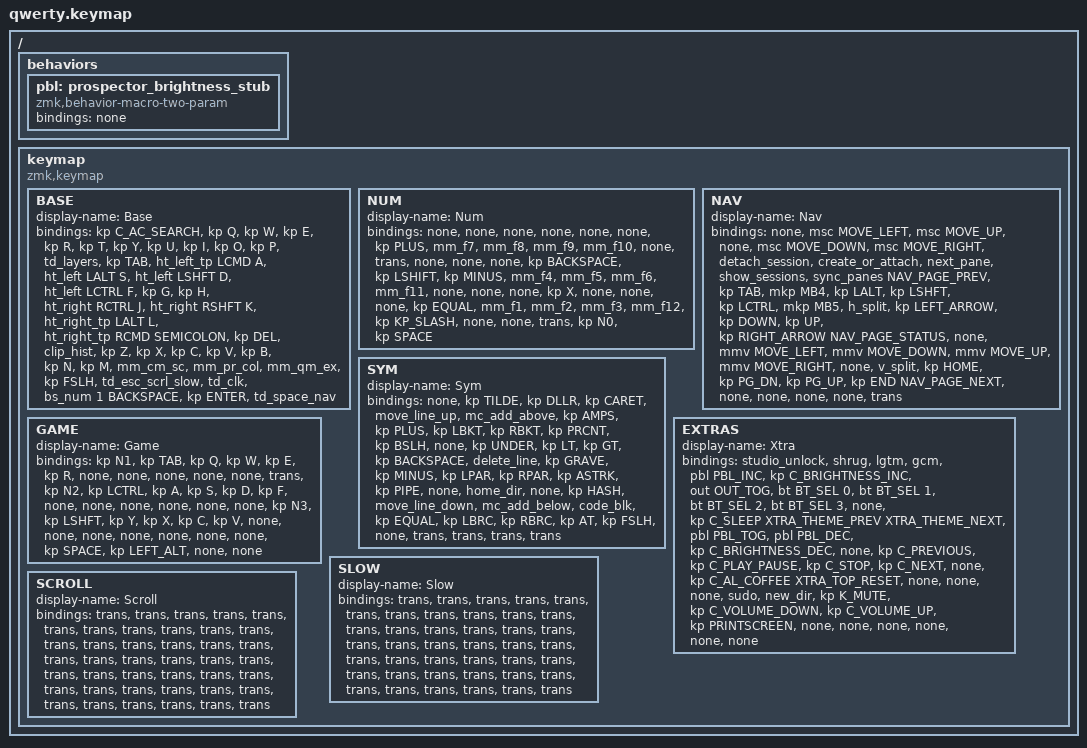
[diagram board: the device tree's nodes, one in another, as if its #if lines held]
/* upstream bindings and behaviors */
#include <behaviors.dtsi>
#include <dt-bindings/zmk/bt.h>
#include <dt-bindings/zmk/keys.h>
#include <dt-bindings/zmk/mouse.h>
#include <dt-bindings/zmk/outputs.h>
#include <behaviors/mouse_keys.dtsi>
#include <dt-bindings/zmk/ext_power.h>

/* The shield-specific overlay provides this before keymap preprocessing. */
#ifdef CHARYBDIS_PROSPECTOR_ADAPTER
#include <dt-bindings/prospector/display_page.h>
#include <dt-bindings/prospector/theme.h>
#define NAV_PAGE_PREV &pdp PDP_PREV
#define NAV_PAGE_STATUS &pdp PDP_STATUS
#define NAV_PAGE_NEXT &pdp PDP_NEXT
#define XTRA_THEME_PREV &pth PTH_PREV
#define XTRA_THEME_NEXT &pth PTH_NEXT
#define XTRA_TOP_RESET &ptr
#else
#define NAV_PAGE_PREV &none
#define NAV_PAGE_STATUS &none
#define NAV_PAGE_NEXT &none
#define XTRA_THEME_PREV &none
#define XTRA_THEME_NEXT &none
#define XTRA_TOP_RESET &none
#endif

/* local overlays */
#include "keymap_features/prospector_brightness.dtsi"
#include "keymap_features/macros.dtsi"
#include "keymap_features/behaviors.dtsi"
#include "keymap_features/combos.dtsi"

/ {
/* --- KEYMAP CONFIG --- */
// ╭──────┬──────┬──────┬──────┬──────┬──────╮  ╭──────┬──────┬──────┬──────┬──────┬──────╮
//    00     01     02     03    04      05        06     07     08     09     10     11
// ├──────┼──────┼──────┼──────┼──────┼──────┤  ├──────┼──────┼──────┼──────┼──────┼──────┤
//    12     13     14     15    16      17        18     19     20     21     22     23
// ├──────┼──────┼──────┼──────┼──────┼──────┤  ├──────┼──────┼──────┼──────┼──────┼──────┤
//    24     25     26     27    28      29        30     31     32     33     34     35
// ╰──────┴──────┴──────┼──────┼──────┼──────┤  ├──────┼──────┼──────┴──────┴──────┴──────╯
//                         36     37     38        39     40
//                      ╰──────┴──────┴──────╯  ╰──────┴──────╯
// #define BASE    0
// #define NUM     1
// #define NAV     2
// #define SYM     3
// #define GAME    4
// #define EXTRAS  5
// #define SLOW    6
// #define SCROLL  7

// This shared keymap builds for prospector and non-prospector firmwares. 
// This stubs the key bindings that are contained in the prospector module
// so non-prospector firmware can build.
#ifndef CONFIG_SHIELD_PROSPECTOR_ADAPTER
    behaviors {
        /omit-if-no-ref/ pbl: prospector_brightness_stub {
            compatible = "zmk,behavior-macro-two-param";
            #binding-cells = <2>;
            bindings = <&none>;
        };
    };
#endif

    keymap {
        compatible = "zmk,keymap";
        BASE {
            display-name = "Base";
            bindings = <
// ╭───────────────┬────────────────┬────────────────┬─────────────────┬─────────────────┬──────╮  ╭──────┬──────────────────┬──────────────────┬─────────────────┬─────────────────┬─────────────╮
    &kp C_AC_SEARCH  &kp Q            &kp W            &kp E             &kp R             &kp T    &kp Y   &kp U              &kp I              &kp O             &kp P           &td_layers
// ├───────────────┼────────────────┼────────────────┼─────────────────┼─────────────────┼──────┤  ├──────┼──────────────────┼──────────────────┼─────────────────┼─────────────────┼─────────────┤
    &kp TAB          &ht_left_tp LCMD A  &ht_left LALT S  &ht_left LSHFT D  &ht_left LCTRL F  &kp G    &kp H   &ht_right RCTRL J  &ht_right RSHFT K  &ht_right_tp LALT L  &ht_right_tp RCMD SEMICOLON   &kp DEL
// ├───────────────┼────────────────┼────────────────┼─────────────────┼─────────────────┼──────┤  ├──────┼──────────────────┼──────────────────┼─────────────────┼─────────────────┼─────────────┤
    &clip_hist       &kp Z            &kp X            &kp C             &kp V             &kp B    &kp N   &kp M              &mm_cm_sc          &mm_pr_col        &mm_qm_ex          &kp FSLH
// ╰───────────────┴────────────────┴────────────────┼─────────────────┼─────────────────┼──────┤  ├──────┼──────────────────┼──────────────────┴─────────────────┴─────────────────┴─────────────╯
                                                             &td_esc_scrl_slow   &td_clk  &bs_num 1 BACKSPACE   &kp ENTER  &td_space_nav
                                                         // ╰──────────────────┴─────────┴──────╯  ╰──────────┴──────────────╯
            >;
        };

        NUM {
            display-name = "Num";
            bindings = <
&none   &none  &none   &none  &none          &none            &kp PLUS     &mm_f7             &mm_f8             &mm_f9             &mm_f10            &none
&trans   &none  &none  &none  &kp BACKSPACE  &kp LSHIFT       &kp MINUS    &mm_f4             &mm_f5             &mm_f6             &mm_f11            &none
&none    &none  &kp X  &none  &none          &none            &kp EQUAL    &mm_f1             &mm_f2             &mm_f3             &mm_f12            &kp KP_SLASH
                       &none  &none          &trans           &kp N0     &kp SPACE
            >;
        };

        NAV {
            display-name = "Nav";
            bindings = <
&none    &msc MOVE_LEFT  &msc MOVE_UP    &none        &msc MOVE_DOWN  &msc MOVE_RIGHT     &detach_session  &create_or_attach  &next_pane   &show_sessions  &sync_panes       NAV_PAGE_PREV
&kp TAB  &mkp MB4        &kp LALT        &kp LSHFT    &kp LCTRL       &mkp MB5            &h_split         &kp LEFT_ARROW     &kp DOWN     &kp UP          &kp RIGHT_ARROW   NAV_PAGE_STATUS
&none    &mmv MOVE_LEFT  &mmv MOVE_DOWN  &mmv MOVE_UP &mmv MOVE_RIGHT &none               &v_split         &kp HOME           &kp PG_DN    &kp PG_UP       &kp END           NAV_PAGE_NEXT
                                                      &none   &none   &none               &none   &trans
            >;
        };

        SYM {
            display-name = "Sym";
            bindings = <
&none  &kp TILDE  &kp DLLR  &kp CARET  &move_line_up    &mc_add_above      &kp AMPS   &kp PLUS     &kp LBKT  &kp RBKT  &kp PRCNT  &kp BSLH
&none  &kp UNDER  &kp LT    &kp GT     &kp BACKSPACE    &delete_line       &kp GRAVE  &kp MINUS    &kp LPAR  &kp RPAR  &kp ASTRK  &kp PIPE
&none  &home_dir  &none     &kp HASH   &move_line_down  &mc_add_below      &code_blk  &kp EQUAL    &kp LBRC  &kp RBRC  &kp AT     &kp FSLH
                                       &none  &trans     &trans            &trans   &trans
            >;
        };

        GAME {
            display-name = "Game";
            bindings = <
&kp N1  &kp TAB    &kp Q  &kp W   &kp E      &kp R           &none  &none  &none  &none  &none  &trans
&kp N2  &kp LCTRL  &kp A  &kp S   &kp D      &kp F           &none  &none  &none  &none  &none  &none
&kp N3  &kp LSHFT  &kp Y  &kp X   &kp C      &kp V           &none  &none  &none  &none  &none  &none
                          &none   &kp SPACE  &kp LEFT_ALT    &none  &none
            >;
        };

        EXTRAS {
            display-name = "Xtra";
            bindings = <
&studio_unlock    &shrug          &lgtm           &gcm            &pbl PBL_INC    &kp C_BRIGHTNESS_INC    &out OUT_TOG  &bt BT_SEL 0    &bt BT_SEL 1       &bt BT_SEL 2      &bt BT_SEL 3     &none
&kp C_SLEEP       XTRA_THEME_PREV XTRA_THEME_NEXT &pbl PBL_TOG    &pbl PBL_DEC    &kp C_BRIGHTNESS_DEC    &none         &kp C_PREVIOUS  &kp C_PLAY_PAUSE   &kp C_STOP        &kp C_NEXT       &none
&kp C_AL_COFFEE   XTRA_TOP_RESET &none           &none           &none          &sudo                   &new_dir      &kp K_MUTE      &kp C_VOLUME_DOWN  &kp C_VOLUME_UP   &kp PRINTSCREEN  &none
                                                                                   &none  &none  &none    &none         &none
            >;
        };

        SLOW {
            display-name = "Slow";
            bindings = <
// ╭────────┬────────┬────────┬────────┬────────┬────────╮  ╭────────┬────────┬────────┬────────┬────────┬────────╮
    &trans    &trans   &trans   &trans   &trans   &trans      &trans   &trans   &trans   &trans   &trans   &trans
// ├────────┼────────┼────────┼────────┼────────┼────────┤  ├────────┼────────┼────────┼────────┼────────┼────────┤
    &trans    &trans   &trans   &trans   &trans   &trans      &trans   &trans   &trans   &trans   &trans   &trans
// ├────────┼────────┼────────┼────────┼────────┼────────┤  ├────────┼────────┼────────┼────────┼────────┼────────┤
    &trans    &trans   &trans   &trans   &trans   &trans      &trans   &trans   &trans   &trans   &trans   &trans
// ╰────────┴────────┴────────┼────────┼────────┼────────┤  ├────────┼────────┼────────┴────────┴────────┴────────╯
                                  &trans   &trans   &trans      &trans   &trans
                             // ╰────────┴────────┴────────╯  ╰────────┴────────╯
            >;
        };

        SCROLL {
            display-name = "Scroll";
            bindings = <
// ╭────────┬────────┬────────┬────────┬────────┬────────╮  ╭────────┬────────┬────────┬────────┬────────┬────────╮
    &trans    &trans   &trans   &trans   &trans   &trans      &trans   &trans   &trans   &trans   &trans   &trans
// ├────────┼────────┼────────┼────────┼────────┼────────┤  ├────────┼────────┼────────┼────────┼────────┼────────┤
    &trans    &trans   &trans   &trans   &trans   &trans      &trans   &trans   &trans   &trans   &trans   &trans
// ├────────┼────────┼────────┼────────┼────────┼────────┤  ├────────┼────────┼────────┼────────┼────────┼────────┤
    &trans    &trans   &trans   &trans   &trans   &trans      &trans   &trans   &trans   &trans   &trans   &trans
// ╰────────┴────────┴────────┼────────┼────────┼────────┤  ├────────┼────────┼────────┴────────┴────────┴────────╯
                                  &trans   &trans   &trans      &trans   &trans
                             // ╰────────┴────────┴────────╯  ╰────────┴────────╯
            >;
        };
    };
};
